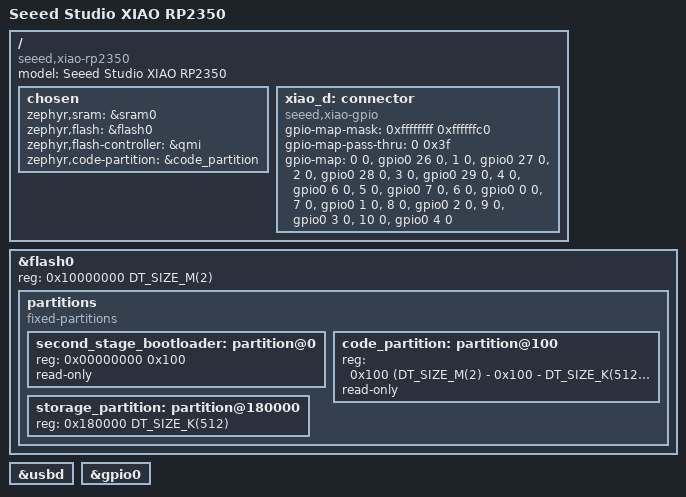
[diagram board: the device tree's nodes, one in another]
/*
 * Copyright (c) 2024 The ZMK Contributors
 * SPDX-License-Identifier: MIT
 */

/dts-v1/;

#include <raspberrypi/rpi_pico/rp2350a.dtsi>
#include <raspberrypi/rpi_pico/m33.dtsi>
#include <raspberrypi/rp2350-boot-mode-retention.dtsi>

/ {
    model = "Seeed Studio XIAO RP2350";
    compatible = "seeed,xiao-rp2350";

    chosen {
        zephyr,sram = &sram0;
        zephyr,flash = &flash0;
        zephyr,flash-controller = &qmi;
        zephyr,code-partition = &code_partition;
    };

    xiao_d: connector {
        compatible = "seeed,xiao-gpio";
        #gpio-cells = <2>;
        gpio-map-mask = <0xffffffff 0xffffffc0>;
        gpio-map-pass-thru = <0 0x3f>;
        gpio-map
            = <0 0 &gpio0 26 0>    /* D0 */
            , <1 0 &gpio0 27 0>    /* D1 */
            , <2 0 &gpio0 28 0>    /* D2 */
            , <3 0 &gpio0 29 0>    /* D3 */
            , <4 0 &gpio0 6 0>     /* D4 */
            , <5 0 &gpio0 7 0>     /* D5 */
            , <6 0 &gpio0 0 0>     /* D6 */
            , <7 0 &gpio0 1 0>     /* D7 */
            , <8 0 &gpio0 2 0>     /* D8 */
            , <9 0 &gpio0 3 0>     /* D9 */
            , <10 0 &gpio0 4 0>    /* D10 */
            ;
    };
};

&flash0 {
    reg = <0x10000000 DT_SIZE_M(2)>;

    partitions {
        compatible = "fixed-partitions";
        #address-cells = <1>;
        #size-cells = <1>;

        second_stage_bootloader: partition@0 {
            reg = <0x00000000 0x100>;
            read-only;
        };

        code_partition: partition@100 {
            reg = <0x100 (DT_SIZE_M(2) - 0x100 - DT_SIZE_K(512))>;
            read-only;
        };

        storage_partition: partition@180000 {
            reg = <0x180000 DT_SIZE_K(512)>;
        };
    };
};

zephyr_udc0: &usbd {
    status = "okay";
};

&gpio0 {
    status = "okay";
};

